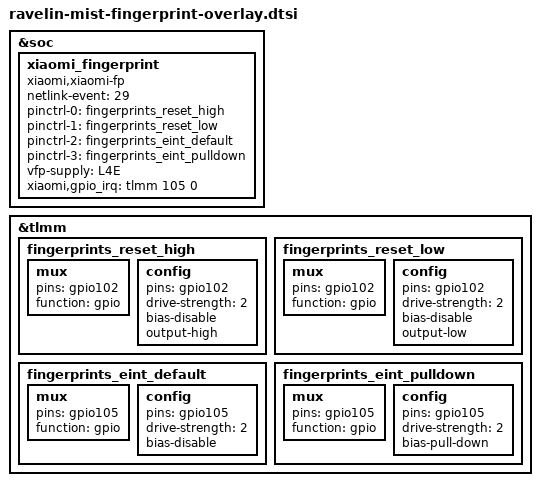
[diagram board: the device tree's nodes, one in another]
// SPDX-License-Identifier: BSD-3-Clause

&soc {
	xiaomi_fingerprint {
		compatible = "xiaomi,xiaomi-fp";
		netlink-event = <29>;
		pinctrl-names = "reset_high", "reset_low", "eint_default", "eint_pulldown";
		pinctrl-0 = <&fingerprints_reset_high>;
		pinctrl-1 = <&fingerprints_reset_low>;
		pinctrl-2 = <&fingerprints_eint_default>;
		pinctrl-3 = <&fingerprints_eint_pulldown>;
		vfp-supply = <&L4E>;
		xiaomi,gpio_irq = <&tlmm 105 0>;
		status = "okay";
	};
};

&tlmm {
	fingerprints_reset_high: fingerprints_reset_high {
		mux {
			pins = "gpio102";
			function = "gpio";
		};

		config {
			pins = "gpio102";
			drive-strength = <2>;
			bias-disable;
			output-high;
		};
	};

	fingerprints_reset_low: fingerprints_reset_low {
		mux {
			pins = "gpio102";
			function = "gpio";
		};

		config {
			pins = "gpio102";
			drive-strength = <2>;
			bias-disable;
			output-low;
		};
	};

	fingerprints_eint_default: fingerprints_eint_default {
		mux {
			pins = "gpio105";
			function = "gpio";
		};

		config {
			pins = "gpio105";
			drive-strength = <2>;
			bias-disable;
		};
	};

	fingerprints_eint_pulldown: fingerprints_eint_pulldown {
		mux {
			pins = "gpio105";
			function = "gpio";
		};

		config {
			pins = "gpio105";
			drive-strength = <2>;
			bias-pull-down;
		};
	};
};
